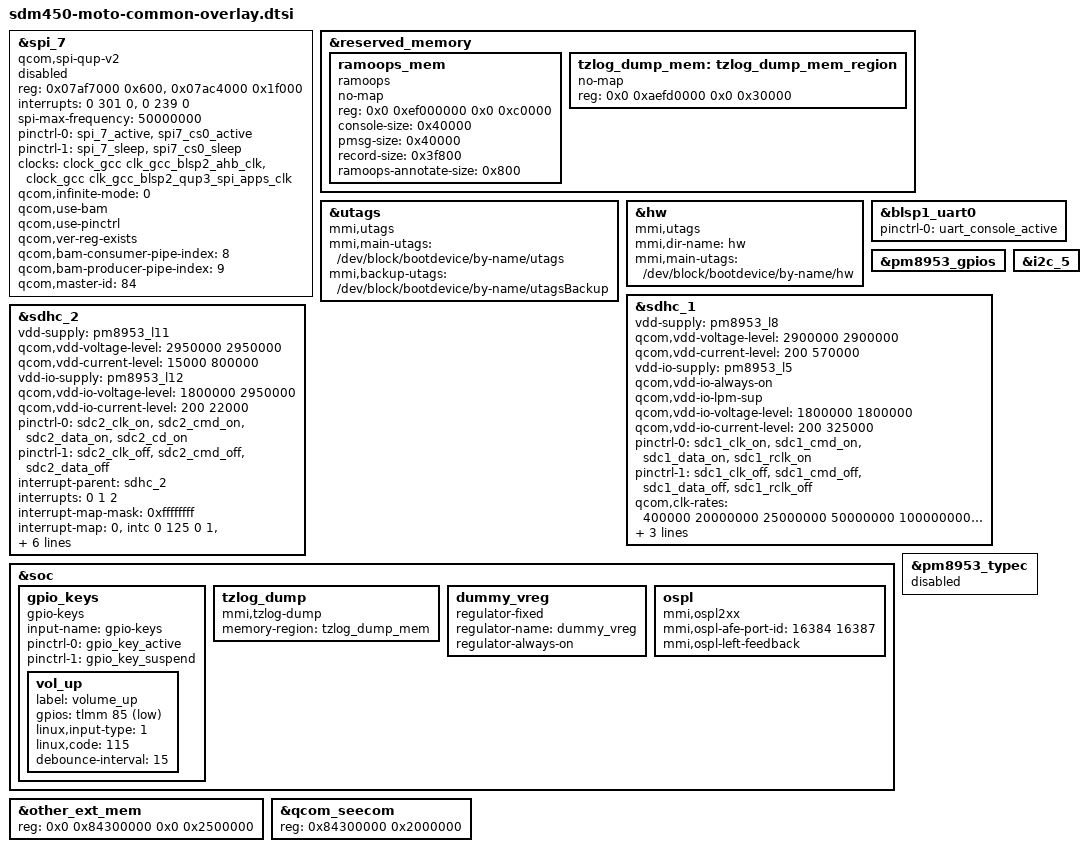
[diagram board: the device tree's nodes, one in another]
/*
 * Copyright (c) 2017-2018, The Linux Foundation. All rights reserved.
 *
 * This program is free software; you can redistribute it and/or modify
 * it under the terms of the GNU General Public License version 2 and
 * only version 2 as published by the Free Software Foundation.
 *
 * This program is distributed in the hope that it will be useful,
 * but WITHOUT ANY WARRANTY; without even the implied warranty of
 * MERCHANTABILITY or FITNESS FOR A PARTICULAR PURPOSE.  See the
 * GNU General Public License for more details.
 */

#include "sdm450-moto-pinctrl-overlay.dtsi"

&spi_7 {
	compatible = "qcom,spi-qup-v2";
	#address-cells = <1>;
	#size-cells = <0>;
	reg-names = "spi_physical", "spi_bam_physical";
	reg = <0x07af7000 0x600>,
	<0x07ac4000 0x1f000>;
	interrupt-names = "spi_irq", "spi_bam_irq";
	interrupts = <0 301 0>, <0 239 0>;
	spi-max-frequency = <50000000>;
	pinctrl-names = "spi_default", "spi_sleep";
	pinctrl-0 = <&spi_7_active &spi7_cs0_active>;
	pinctrl-1 = <&spi_7_sleep &spi7_cs0_sleep>;
	clocks = <&clock_gcc clk_gcc_blsp2_ahb_clk>,
		<&clock_gcc clk_gcc_blsp2_qup3_spi_apps_clk>;
	clock-names = "iface_clk", "core_clk";
	qcom,infinite-mode = <0>;
	qcom,use-bam;
	qcom,use-pinctrl;
	qcom,ver-reg-exists;
	qcom,bam-consumer-pipe-index = <8>;
	qcom,bam-producer-pipe-index = <9>;
	qcom,master-id = <84>;
	status = "disabled";
};

&reserved_memory {
	ramoops_mem {
		compatible = "ramoops";
		no-map;
		reg = <0x0 0xef000000 0x0 0xc0000>;
		console-size = <0x40000>;
		pmsg-size = <0x40000>;
		record-size = <0x3f800>;
		ramoops-annotate-size = <0x800>;
	};

	tzlog_dump_mem: tzlog_dump_mem_region {
		no-map;
		reg = <0x0 0xaefd0000 0x0 0x30000>;
	};
};

&utags {
	compatible = "mmi,utags";
	mmi,main-utags = "/dev/block/bootdevice/by-name/utags";
	mmi,backup-utags = "/dev/block/bootdevice/by-name/utagsBackup";
};

&hw {
	compatible = "mmi,utags";
	mmi,dir-name = "hw";
	mmi,main-utags = "/dev/block/bootdevice/by-name/hw";
};

&blsp1_uart0 {
	status = "ok";
	pinctrl-names = "default";
	pinctrl-0 = <&uart_console_active>;
};

&pm8953_gpios {

};

&i2c_5 { /* BLSP2 QUP1 (NFC) */
	status = "ok";
};

&sdhc_1 {
	/* device core power supply */
	vdd-supply = <&pm8953_l8>;
	qcom,vdd-voltage-level = <2900000 2900000>;
	qcom,vdd-current-level = <200 570000>;

	/* device communication power supply */
	vdd-io-supply = <&pm8953_l5>;
	qcom,vdd-io-always-on;
	qcom,vdd-io-lpm-sup;
	qcom,vdd-io-voltage-level = <1800000 1800000>;
	qcom,vdd-io-current-level = <200 325000>;

	pinctrl-names = "active", "sleep";
	pinctrl-0 = <&sdc1_clk_on &sdc1_cmd_on &sdc1_data_on  &sdc1_rclk_on>;
	pinctrl-1 = <&sdc1_clk_off &sdc1_cmd_off &sdc1_data_off &sdc1_rclk_off>;

	qcom,clk-rates = <400000 20000000 25000000 50000000 100000000 192000000
								384000000>;
	qcom,nonremovable;
	qcom,bus-speed-mode = "HS400_1p8v", "HS200_1p8v", "DDR_1p8v";

	status = "ok";
};

&sdhc_2 {
	/* device core power supply */
	vdd-supply = <&pm8953_l11>;
	qcom,vdd-voltage-level = <2950000 2950000>;
	qcom,vdd-current-level = <15000 800000>;

	/* device communication power supply */
	vdd-io-supply = <&pm8953_l12>;
	qcom,vdd-io-voltage-level = <1800000 2950000>;
	qcom,vdd-io-current-level = <200 22000>;

	pinctrl-names = "active", "sleep";
	pinctrl-0 = <&sdc2_clk_on &sdc2_cmd_on &sdc2_data_on &sdc2_cd_on>;
	pinctrl-1 = <&sdc2_clk_off &sdc2_cmd_off &sdc2_data_off>;

	#address-cells = <0>;
	interrupt-parent = <&sdhc_2>;
	interrupts = <0 1 2>;
	#interrupt-cells = <1>;
	interrupt-map-mask = <0xffffffff>;
	interrupt-map = <0 &intc 0 125 0
		1 &intc 0 221 0
		2 &tlmm 133 0>;
	interrupt-names = "hc_irq", "pwr_irq", "status_irq";
	cd-gpios = <&tlmm 133 0x1>;

	qcom,clk-rates = <400000 20000000 25000000 50000000 100000000
								200000000>;
	qcom,bus-speed-mode = "SDR12", "SDR25", "SDR50", "DDR50", "SDR104";

	status = "ok";
};

&soc {
	gpio_keys {
		compatible = "gpio-keys";
		input-name = "gpio-keys";
		pinctrl-names = "tlmm_gpio_key_active","tlmm_gpio_key_suspend";
		pinctrl-0 = <&gpio_key_active>;
		pinctrl-1 = <&gpio_key_suspend>;

		vol_up {
			label = "volume_up";
			gpios = <&tlmm 85 0x1>;
			linux,input-type = <1>;
			linux,code = <115>;
			debounce-interval = <15>;
		};
	};

	tzlog_dump {
		compatible = "mmi,tzlog-dump";
		memory-region = <&tzlog_dump_mem>;
	};
};

&soc{
	dummy_vreg: dummy_vreg {
		compatible = "regulator-fixed";
		status = "ok";
		regulator-name = "dummy_vreg";
		regulator-always-on;
	};
	ospl {
		compatible = "mmi,ospl2xx";
		status = "ok";
		mmi,ospl-afe-port-id = <16384 16387>;
		mmi,ospl-left-feedback;
	};
};

&pm8953_typec {
	status = "disabled";
};

&other_ext_mem {
	reg = <0x0 0x84300000 0x0 0x2500000>;
};

&qcom_seecom {
	reg = <0x84300000 0x2000000>;
};
